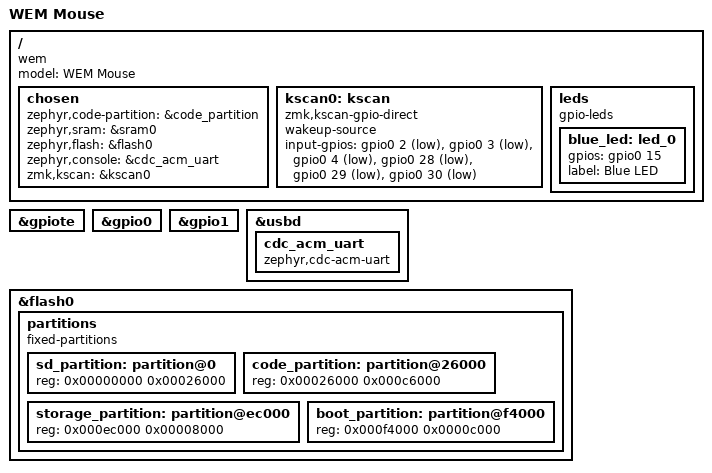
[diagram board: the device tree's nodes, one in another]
/*
 * Copyright (c) 2024
 * SPDX-License-Identifier: MIT
 */

/dts-v1/;
#include <nordic/nrf52840_qiaa.dtsi>

/ {
	model = "WEM Mouse";
	compatible = "wem";

	chosen {
		zephyr,code-partition = &code_partition;
		zephyr,sram = &sram0;
		zephyr,flash = &flash0;
		zephyr,console = &cdc_acm_uart;
		zmk,kscan = &kscan0;
	};

	kscan0: kscan {
		compatible = "zmk,kscan-gpio-direct";
		wakeup-source;

		input-gpios
			= <&gpio0 2 (GPIO_ACTIVE_LOW | GPIO_PULL_UP)>  // LMB
			, <&gpio0 3 (GPIO_ACTIVE_LOW | GPIO_PULL_UP)>  // MMB
			, <&gpio0 4 (GPIO_ACTIVE_LOW | GPIO_PULL_UP)>  // RMB
			, <&gpio0 28 (GPIO_ACTIVE_LOW | GPIO_PULL_UP)> // Back
			, <&gpio0 29 (GPIO_ACTIVE_LOW | GPIO_PULL_UP)> // Forward
			, <&gpio0 30 (GPIO_ACTIVE_LOW | GPIO_PULL_UP)> // F13
			;
	};

	leds {
		compatible = "gpio-leds";
		blue_led: led_0 {
			gpios = <&gpio0 15 GPIO_ACTIVE_HIGH>;
			label = "Blue LED";
		};
	};
};

&gpiote {
	status = "okay";
};

&gpio0 {
	status = "okay";
};

&gpio1 {
	status = "okay";
};

&usbd {
	status = "okay";
	cdc_acm_uart: cdc_acm_uart {
		compatible = "zephyr,cdc-acm-uart";
	};
};

&flash0 {
	/*
	 * For more information, see:
	 * http://docs.zephyrproject.org/latest/devices/dts/flash_partitions.html
	 */
	partitions {
		compatible = "fixed-partitions";
		#address-cells = <1>;
		#size-cells = <1>;

		sd_partition: partition@0 {
			reg = <0x00000000 0x00026000>;
		};
		code_partition: partition@26000 {
			reg = <0x00026000 0x000c6000>;
		};

		/*
		 * The flash starting at 0x000ec000 and ending at
		 * 0x000f3fff is reserved for use by the application.
		 */

		/*
		 * Storage partition will be used by FCB/LittleFS/NVS
		 * if enabled.
		 */
		storage_partition: partition@ec000 {
			reg = <0x000ec000 0x00008000>;
		};

		boot_partition: partition@f4000 {
			reg = <0x000f4000 0x0000c000>;
		};
	};
};
